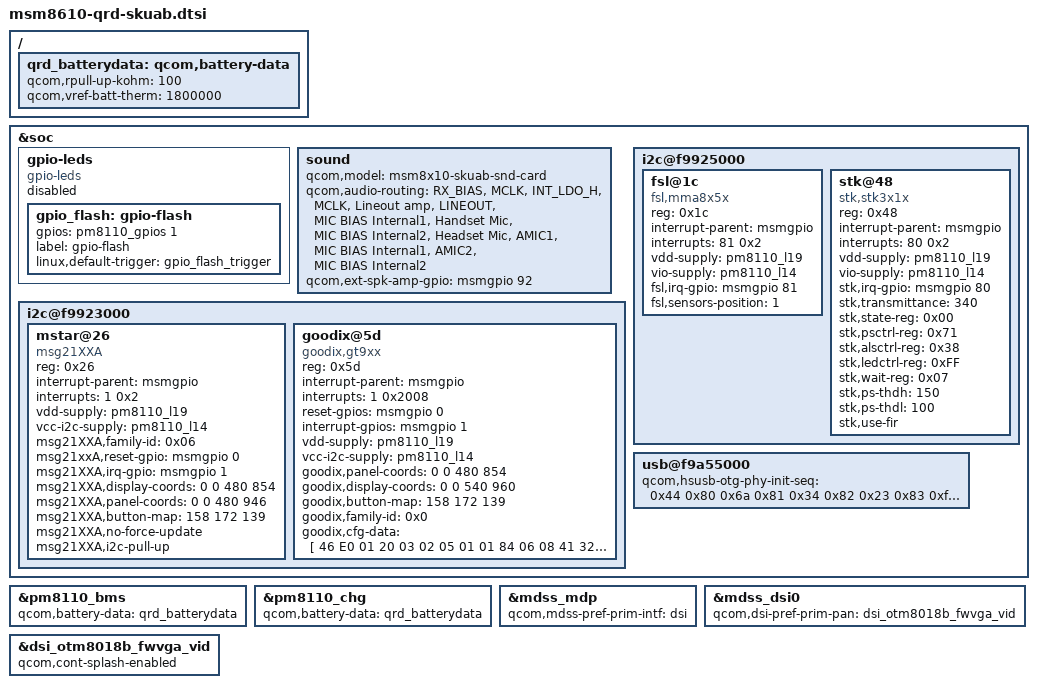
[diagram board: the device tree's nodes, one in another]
/* Copyright (c) 2013, The Linux Foundation. All rights reserved.
 *
 * This program is free software; you can redistribute it and/or modify
 * it under the terms of the GNU General Public License version 2 and
 * only version 2 as published by the Free Software Foundation.
 *
 * This program is distributed in the hope that it will be useful,
 * but WITHOUT ANY WARRANTY; without even the implied warranty of
 * MERCHANTABILITY or FITNESS FOR A PARTICULAR PURPOSE.  See the
 * GNU General Public License for more details.
 */

/include/ "msm8610-qrd.dtsi"

&soc {
	gpio-leds {
		compatible = "gpio-leds";
		status = "disabled";

		gpio_flash: gpio-flash {
			gpios = <&pm8110_gpios 1 0>;
			label = "gpio-flash";
			linux,default-trigger = "gpio_flash_trigger";
		};
	};
    sound {
        qcom,model = "msm8x10-skuab-snd-card";

        qcom,audio-routing =
            "RX_BIAS", "MCLK",
            "INT_LDO_H", "MCLK",
            "Lineout amp", "LINEOUT",
            "MIC BIAS Internal1", "Handset Mic",
            "MIC BIAS Internal2", "Headset Mic",
            "AMIC1", "MIC BIAS Internal1",
            "AMIC2", "MIC BIAS Internal2";

        qcom,ext-spk-amp-gpio = <&msmgpio 92 0x0>;
    };
    i2c@f9923000{
/*
		focaltech@38{
			compatible = "focaltech,5x06";
			reg = <0x38>;
			interrupt-parent = <&msmgpio>;
			interrupts = <1 0x2>;
			vdd-supply = <&pm8110_l19>;
			vcc_i2c-supply = <&pm8110_l14>;
			focaltech,family-id = <0x06>;
			focaltech,reset-gpio = <&msmgpio 0 0x00>;
			focaltech,irq-gpio = <&msmgpio 1 0x00>;
			focaltech,display-coords = <0 0 480 854>;
			focaltech,panel-coords = <0 0 480 946>;
			focaltech,button-map= <139 102 158>;
			focaltech,no-force-update;
			focaltech,i2c-pull-up;
		};
	gen-vkeys {
		compatible = "qcom,gen-vkeys";
		label = "ft5x06_ts";
		qcom,disp-maxx = <480>;
		qcom,disp-maxy = <854>;
		qcom,panel-maxx = <481>;
		qcom,panel-maxy = <946>;
		qcom,key-codes = <139 102 158>;
		qcom,y-offset = <0>;
	};
*/
		mstar@26{
			compatible = "msg21XXA";
			reg = <0x26>;
			interrupt-parent = <&msmgpio>;
			interrupts = <1 0x2>;
			vdd-supply = <&pm8110_l19>;
			vcc-i2c-supply = <&pm8110_l14>;
			msg21XXA,family-id = <0x06>;
			msg21xxA,reset-gpio = <&msmgpio 0 0x00>;
			msg21XXA,irq-gpio = <&msmgpio 1 0x00>;
			msg21XXA,display-coords = <0 0 480 854>;
			msg21XXA,panel-coords = <0 0 480 946>;
			msg21XXA,button-map= <158 172 139>;
			msg21XXA,no-force-update;
			msg21XXA,i2c-pull-up;
		};
		goodix@5d {
			compatible = "goodix,gt9xx";
			reg = <0x5d>;
			interrupt-parent = <&msmgpio>;
			interrupts = <1 0x2008>;
			reset-gpios = <&msmgpio 0 0x00>;
			interrupt-gpios = <&msmgpio 1 0x00>;
			vdd-supply = <&pm8110_l19>;
			vcc-i2c-supply = <&pm8110_l14>;
			goodix,panel-coords = <0 0 480 854>;
			goodix,display-coords = <0 0 540 960>;
			goodix,button-map= <158 172 139>;
			goodix,family-id = <0x0>;
			goodix,cfg-data = [
				46 E0 01 20 03 02 05 01 01 84
				06 08 41 32 03 05 00 00 00 00
				00 10 00 20 04 00 33 03 24 88
				46 48 D9 0B 05 07 00 43 01 1D
				00 01 05 05 03 03 5D AA 84 C4
				46 28 5A 54 C5 02 07 00 00 01
				D5 2B 00 BE 33 00 8B 3C 00 80
				46 00 6B 53 00 6B 08 0B 10 00
				81 40 30 FF FF 1F 04 00 00 1E
				00 01 0D 0C 09 0F 00 00 01 03
				00 00 00 00 00 00 00 00 00 00
				00 00 00 01 02 03 04 05 06 07
				08 09 0C 0D 0E 0F 10 11 FF FF
				00 00 00 00 00 00 00 00 00 00
				00 00 08 09 0A 24 26 27 28 FF
				FF FF 00 00 00 00 00 00 00 00
				00 00 00 FF FF 0B 25 FF FF FF
				FF FF FF FF FF FF FF FF FF FF
				FF FF FF FF 96 96 96 96 DC 00
				00 00 00 00 00 00 00 0C 0A 0C
				0C 00 00 00 00 00 00 00 00 00
				01 01 00 00 00 00 03 01 00 00
				00 00 00 00 00 00 78 01];
		};
	};

    i2c@f9925000 {
		fsl@1c {
			compatible = "fsl,mma8x5x";
			reg = <0x1c>;
			interrupt-parent = <&msmgpio>;
			interrupts = <81 0x2>;
			vdd-supply = <&pm8110_l19>;
			vio-supply = <&pm8110_l14>;
			fsl,irq-gpio = <&msmgpio 81 0x00>;
			fsl,sensors-position = <1>;
		};
		stk@48 {
			compatible = "stk,stk3x1x";
			reg = <0x48>;
			interrupt-parent = <&msmgpio>;
			interrupts = <80 0x2>;
			vdd-supply = <&pm8110_l19>;
			vio-supply = <&pm8110_l14>;
			stk,irq-gpio = <&msmgpio 80 0x02>;
			stk,transmittance = <340>;
			stk,state-reg = <0x00>;
			stk,psctrl-reg = <0x71>;
			stk,alsctrl-reg = <0x38>;
			stk,ledctrl-reg = <0xFF>;
			stk,wait-reg = <0x07>;
			stk,ps-thdh = <150>;
			stk,ps-thdl = <100>;
			stk,use-fir;
		};
	};

	usb@f9a55000 {
               qcom,hsusb-otg-phy-init-seq =
                       <0x44 0x80 0x6a 0x81 0x34 0x82 0x23 0x83 0xffffffff>;
	};
};

/ {
	qrd_batterydata: qcom,battery-data {
		qcom,rpull-up-kohm = <100>;
		qcom,vref-batt-therm = <1800000>;

		/include/ "batterydata-e550w-4v2-1700mah.dtsi"
	};
};

&pm8110_bms {
	status = "ok";
	qcom,battery-data = <&qrd_batterydata>;
};

&pm8110_chg {
	qcom,battery-data = <&qrd_batterydata>;
};

&mdss_mdp {
	qcom,mdss-pref-prim-intf = "dsi";
};

&mdss_dsi0 {
	qcom,dsi-pref-prim-pan = <&dsi_otm8018b_fwvga_vid>;
};

&dsi_otm8018b_fwvga_vid {
	qcom,cont-splash-enabled;
};
